VERSION ""

NS_ :

BS_:

BU_: FL_Wheel FR_Wheel BL_Wheel BR_Wheel Brake_Pressure Temp_Board Motion_Board Logger_Board BMS E_Throttle PDM IMD VCU

BO_ 3221225472 VECTOR__INDEPENDENT_SIG_MSG: 0 Vector__XXX
 SG_ Left_ADC : 0|16@1+ (1,0) [0|0] "" Vector__XXX
 SG_ Right_ADC : 16|16@1+ (1,0) [0|0] "" Vector__XXX
 SG_ Brake_ADC : 32|16@1+ (1,0) [0|0] "" Vector__XXX

BO_ 1024 FL_Wheel: 4 FL_Wheel
 SG_ FL_Wheel_Speed : 0|16@1+ (0.1,0) [0|0] "mph" Vector__XXX
 SG_ FL_Brake_Temperature : 16|16@1+ (0.1,-40) [0|0] "C" Vector__XXX

BO_ 1025 FR_Wheel: 4 FR_Wheel
 SG_ FR_Wheel_Speed : 0|16@1+ (0.1,0) [0|0] "mph" Vector__XXX
 SG_ FR_Brake_Temperature : 16|16@1+ (0.1,-40) [0|0] "C" Vector__XXX

BO_ 1026 BL_Wheel: 4 BL_Wheel
 SG_ BL_Wheel_Speed : 0|16@1+ (0.1,0) [0|0] "mph" Vector__XXX
 SG_ BL_Brake_Temperature : 16|16@1+ (0.1,-40) [0|0] "C" Vector__XXX

BO_ 1027 BR_Wheel: 4 BR_Wheel
 SG_ BR_Wheel_Speed : 0|16@1+ (0.1,0) [0|0] "mph" Vector__XXX
 SG_ BR_Brake_Temperature : 16|16@1+ (0.1,-40) [0|0] "C" Vector__XXX

BO_ 1056 Ptrain_Temps: 6 Temp_Board
 SG_ Motor_Temperature : 0|16@1+ (0.1,-40) [0|0] "C" Vector__XXX
 SG_ Coolant_Temperature : 16|16@1+ (0.1,-40) [0|0] "C" Vector__XXX
 SG_ Ambient_Temperature : 32|16@1+ (0.1,-40) [0|0] "C" Vector__XXX

BO_ 1072 GPS: 8 Motion_Board
 SG_ Latitude : 0|32@1- (1,0) [0|0] "1e-7 degrees" Vector__XXX
 SG_ Longitude : 32|32@1- (1,0) [0|0] "1e-7 degrees" Vector__XXX

BO_ 1073 Accelerometer: 6 Motion_Board
 SG_ Accel_X : 0|16@1- (0.0005,0) [0|0] "G" Vector__XXX
 SG_ Accel_Y : 16|16@1- (0.0005,0) [0|0] "G" Vector__XXX
 SG_ Accel_Z : 32|16@1- (0.0005,0) [0|0] "G" Vector__XXX

BO_ 1074 Gyroscope: 6 Motion_Board
 SG_ Gyro_X : 0|16@1- (0.0005,0) [0|0] "rad/s" Vector__XXX
 SG_ Gyro_Y : 16|16@1- (0.0005,0) [0|0] "rad/s" Vector__XXX
 SG_ Gyro_Z : 32|16@1- (0.0005,0) [0|0] "rad/s" Vector__XXX

BO_ 1088 RTC: 4 Logger_Board
 SG_ RTC : 0|32@1+ (1,0) [0|0] "s" Vector__XXX

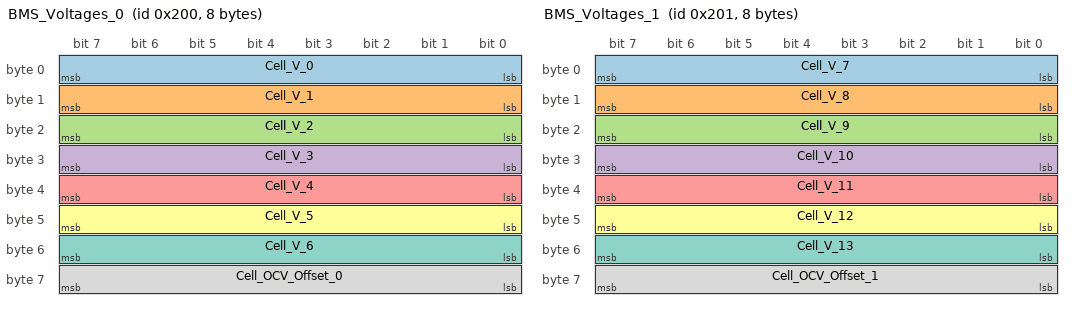
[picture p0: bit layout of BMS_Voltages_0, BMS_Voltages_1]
BO_ 512 BMS_Voltages_0: 8 BMS
 SG_ Cell_V_0 : 0|8@1+ (0.012,2) [0|0] "V" Vector__XXX
 SG_ Cell_V_1 : 8|8@1+ (0.012,2) [0|0] "V" Vector__XXX
 SG_ Cell_V_2 : 16|8@1+ (0.012,2) [0|0] "V" Vector__XXX
 SG_ Cell_V_3 : 24|8@1+ (0.012,2) [0|0] "V" Vector__XXX
 SG_ Cell_V_4 : 32|8@1+ (0.012,2) [0|0] "V" Vector__XXX
 SG_ Cell_V_5 : 40|8@1+ (0.012,2) [0|0] "V" Vector__XXX
 SG_ Cell_V_6 : 48|8@1+ (0.012,2) [0|0] "V" Vector__XXX
 SG_ Cell_OCV_Offset_0 : 56|8@1+ (0.004,0) [0|0] "V" Vector__XXX

BO_ 513 BMS_Voltages_1: 8 BMS
 SG_ Cell_V_7 : 0|8@1+ (0.012,2) [0|0] "V" Vector__XXX
 SG_ Cell_V_8 : 8|8@1+ (0.012,2) [0|0] "V" Vector__XXX
 SG_ Cell_V_9 : 16|8@1+ (0.012,2) [0|0] "V" Vector__XXX
 SG_ Cell_V_10 : 24|8@1+ (0.012,2) [0|0] "V" Vector__XXX
 SG_ Cell_V_11 : 32|8@1+ (0.012,2) [0|0] "V" Vector__XXX
 SG_ Cell_V_12 : 40|8@1+ (0.012,2) [0|0] "V" Vector__XXX
 SG_ Cell_V_13 : 48|8@1+ (0.012,2) [0|0] "V" Vector__XXX
 SG_ Cell_OCV_Offset_1 : 56|8@1+ (0.004,0) [0|0] "V" Vector__XXX

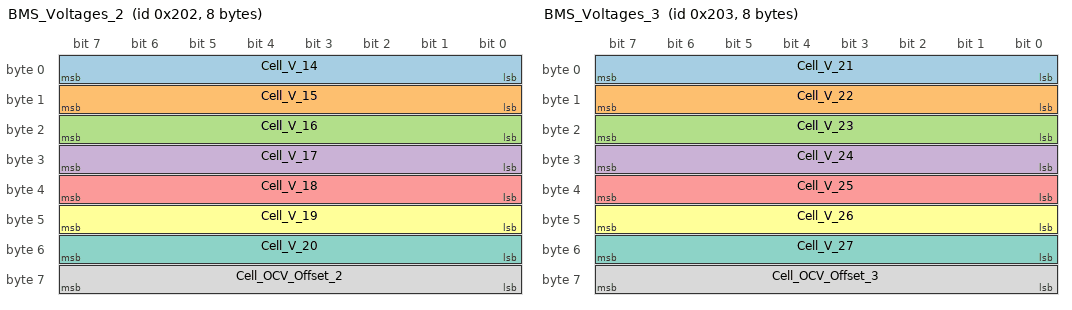
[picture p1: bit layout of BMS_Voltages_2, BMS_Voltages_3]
BO_ 514 BMS_Voltages_2: 8 BMS
 SG_ Cell_V_14 : 0|8@1+ (0.012,2) [0|0] "V" Vector__XXX
 SG_ Cell_V_15 : 8|8@1+ (0.012,2) [0|0] "V" Vector__XXX
 SG_ Cell_V_16 : 16|8@1+ (0.012,2) [0|0] "V" Vector__XXX
 SG_ Cell_V_17 : 24|8@1+ (0.012,2) [0|0] "V" Vector__XXX
 SG_ Cell_V_18 : 32|8@1+ (0.012,2) [0|0] "V" Vector__XXX
 SG_ Cell_V_19 : 40|8@1+ (0.012,2) [0|0] "V" Vector__XXX
 SG_ Cell_V_20 : 48|8@1+ (0.012,2) [0|0] "V" Vector__XXX
 SG_ Cell_OCV_Offset_2 : 56|8@1+ (0.004,0) [0|0] "V" Vector__XXX

BO_ 515 BMS_Voltages_3: 8 BMS
 SG_ Cell_V_21 : 0|8@1+ (0.012,2) [0|0] "V" Vector__XXX
 SG_ Cell_V_22 : 8|8@1+ (0.012,2) [0|0] "V" Vector__XXX
 SG_ Cell_V_23 : 16|8@1+ (0.012,2) [0|0] "V" Vector__XXX
 SG_ Cell_V_24 : 24|8@1+ (0.012,2) [0|0] "V" Vector__XXX
 SG_ Cell_V_25 : 32|8@1+ (0.012,2) [0|0] "V" Vector__XXX
 SG_ Cell_V_26 : 40|8@1+ (0.012,2) [0|0] "V" Vector__XXX
 SG_ Cell_V_27 : 48|8@1+ (0.012,2) [0|0] "V" Vector__XXX
 SG_ Cell_OCV_Offset_3 : 56|8@1+ (0.004,0) [0|0] "V" Vector__XXX

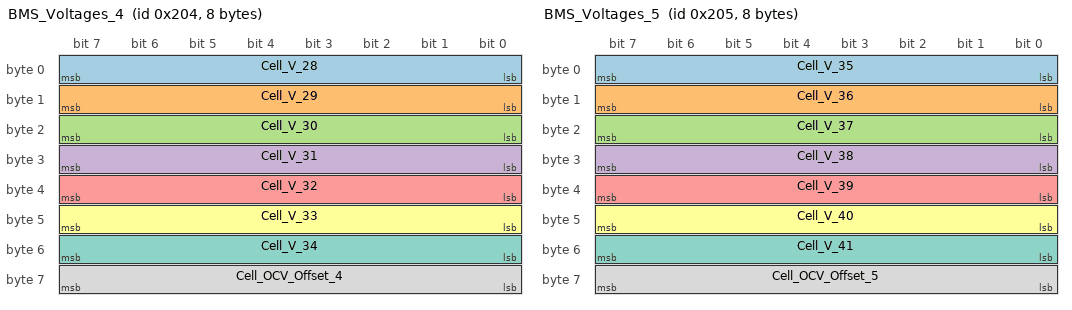
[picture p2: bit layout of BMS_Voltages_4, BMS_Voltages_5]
BO_ 516 BMS_Voltages_4: 8 BMS
 SG_ Cell_V_28 : 0|8@1+ (0.012,2) [0|0] "V" Vector__XXX
 SG_ Cell_V_29 : 8|8@1+ (0.012,2) [0|0] "V" Vector__XXX
 SG_ Cell_V_30 : 16|8@1+ (0.012,2) [0|0] "V" Vector__XXX
 SG_ Cell_V_31 : 24|8@1+ (0.012,2) [0|0] "V" Vector__XXX
 SG_ Cell_V_32 : 32|8@1+ (0.012,2) [0|0] "V" Vector__XXX
 SG_ Cell_V_33 : 40|8@1+ (0.012,2) [0|0] "V" Vector__XXX
 SG_ Cell_V_34 : 48|8@1+ (0.012,2) [0|0] "V" Vector__XXX
 SG_ Cell_OCV_Offset_4 : 56|8@1+ (0.004,0) [0|0] "V" Vector__XXX

BO_ 517 BMS_Voltages_5: 8 BMS
 SG_ Cell_V_35 : 0|8@1+ (0.012,2) [0|0] "V" Vector__XXX
 SG_ Cell_V_36 : 8|8@1+ (0.012,2) [0|0] "V" Vector__XXX
 SG_ Cell_V_37 : 16|8@1+ (0.012,2) [0|0] "V" Vector__XXX
 SG_ Cell_V_38 : 24|8@1+ (0.012,2) [0|0] "V" Vector__XXX
 SG_ Cell_V_39 : 32|8@1+ (0.012,2) [0|0] "V" Vector__XXX
 SG_ Cell_V_40 : 40|8@1+ (0.012,2) [0|0] "V" Vector__XXX
 SG_ Cell_V_41 : 48|8@1+ (0.012,2) [0|0] "V" Vector__XXX
 SG_ Cell_OCV_Offset_5 : 56|8@1+ (0.004,0) [0|0] "V" Vector__XXX

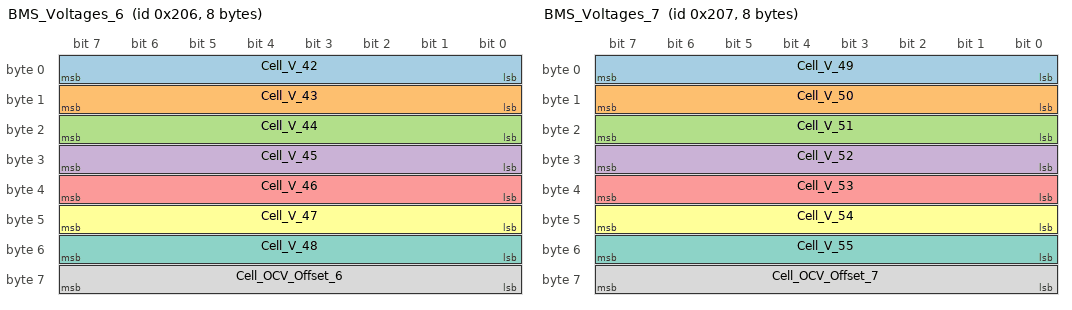
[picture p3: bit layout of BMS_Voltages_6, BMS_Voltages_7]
BO_ 518 BMS_Voltages_6: 8 BMS
 SG_ Cell_V_42 : 0|8@1+ (0.012,2) [0|0] "V" Vector__XXX
 SG_ Cell_V_43 : 8|8@1+ (0.012,2) [0|0] "V" Vector__XXX
 SG_ Cell_V_44 : 16|8@1+ (0.012,2) [0|0] "V" Vector__XXX
 SG_ Cell_V_45 : 24|8@1+ (0.012,2) [0|0] "V" Vector__XXX
 SG_ Cell_V_46 : 32|8@1+ (0.012,2) [0|0] "V" Vector__XXX
 SG_ Cell_V_47 : 40|8@1+ (0.012,2) [0|0] "V" Vector__XXX
 SG_ Cell_V_48 : 48|8@1+ (0.012,2) [0|0] "V" Vector__XXX
 SG_ Cell_OCV_Offset_6 : 56|8@1+ (0.004,0) [0|0] "V" Vector__XXX

BO_ 519 BMS_Voltages_7: 8 BMS
 SG_ Cell_V_49 : 0|8@1+ (0.012,2) [0|0] "V" Vector__XXX
 SG_ Cell_V_50 : 8|8@1+ (0.012,2) [0|0] "V" Vector__XXX
 SG_ Cell_V_51 : 16|8@1+ (0.012,2) [0|0] "V" Vector__XXX
 SG_ Cell_V_52 : 24|8@1+ (0.012,2) [0|0] "V" Vector__XXX
 SG_ Cell_V_53 : 32|8@1+ (0.012,2) [0|0] "V" Vector__XXX
 SG_ Cell_V_54 : 40|8@1+ (0.012,2) [0|0] "V" Vector__XXX
 SG_ Cell_V_55 : 48|8@1+ (0.012,2) [0|0] "V" Vector__XXX
 SG_ Cell_OCV_Offset_7 : 56|8@1+ (0.004,0) [0|0] "V" Vector__XXX

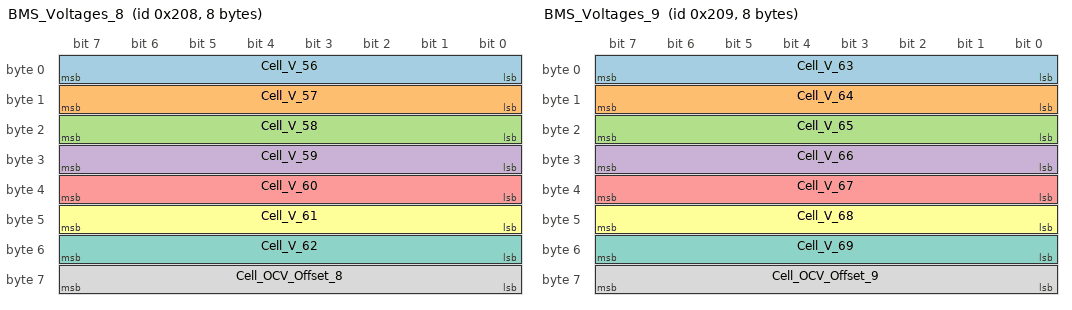
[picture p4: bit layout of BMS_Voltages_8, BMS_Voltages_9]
BO_ 520 BMS_Voltages_8: 8 BMS
 SG_ Cell_V_56 : 0|8@1+ (0.012,2) [0|0] "V" Vector__XXX
 SG_ Cell_V_57 : 8|8@1+ (0.012,2) [0|0] "V" Vector__XXX
 SG_ Cell_V_58 : 16|8@1+ (0.012,2) [0|0] "V" Vector__XXX
 SG_ Cell_V_59 : 24|8@1+ (0.012,2) [0|0] "V" Vector__XXX
 SG_ Cell_V_60 : 32|8@1+ (0.012,2) [0|0] "V" Vector__XXX
 SG_ Cell_V_61 : 40|8@1+ (0.012,2) [0|0] "V" Vector__XXX
 SG_ Cell_V_62 : 48|8@1+ (0.012,2) [0|0] "V" Vector__XXX
 SG_ Cell_OCV_Offset_8 : 56|8@1+ (0.004,0) [0|0] "V" Vector__XXX

BO_ 521 BMS_Voltages_9: 8 BMS
 SG_ Cell_V_63 : 0|8@1+ (0.012,2) [0|0] "V" Vector__XXX
 SG_ Cell_V_64 : 8|8@1+ (0.012,2) [0|0] "V" Vector__XXX
 SG_ Cell_V_65 : 16|8@1+ (0.012,2) [0|0] "V" Vector__XXX
 SG_ Cell_V_66 : 24|8@1+ (0.012,2) [0|0] "V" Vector__XXX
 SG_ Cell_V_67 : 32|8@1+ (0.012,2) [0|0] "V" Vector__XXX
 SG_ Cell_V_68 : 40|8@1+ (0.012,2) [0|0] "V" Vector__XXX
 SG_ Cell_V_69 : 48|8@1+ (0.012,2) [0|0] "V" Vector__XXX
 SG_ Cell_OCV_Offset_9 : 56|8@1+ (0.004,0) [0|0] "V" Vector__XXX

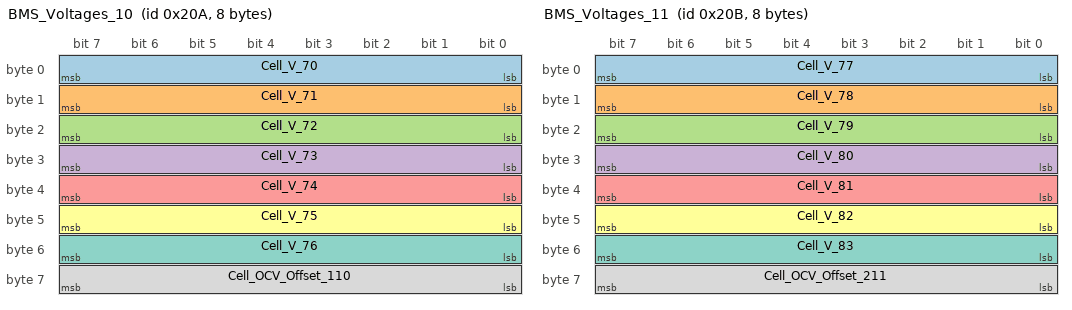
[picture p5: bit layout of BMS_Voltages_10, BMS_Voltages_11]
BO_ 522 BMS_Voltages_10: 8 BMS
 SG_ Cell_V_70 : 0|8@1+ (0.012,2) [0|0] "V" Vector__XXX
 SG_ Cell_V_71 : 8|8@1+ (0.012,2) [0|0] "V" Vector__XXX
 SG_ Cell_V_72 : 16|8@1+ (0.012,2) [0|0] "V" Vector__XXX
 SG_ Cell_V_73 : 24|8@1+ (0.012,2) [0|0] "V" Vector__XXX
 SG_ Cell_V_74 : 32|8@1+ (0.012,2) [0|0] "V" Vector__XXX
 SG_ Cell_V_75 : 40|8@1+ (0.012,2) [0|0] "V" Vector__XXX
 SG_ Cell_V_76 : 48|8@1+ (0.012,2) [0|0] "V" Vector__XXX
 SG_ Cell_OCV_Offset_110 : 56|8@1+ (0.004,0) [0|0] "V" Vector__XXX

BO_ 523 BMS_Voltages_11: 8 BMS
 SG_ Cell_V_77 : 0|8@1+ (0.012,2) [0|0] "V" Vector__XXX
 SG_ Cell_V_78 : 8|8@1+ (0.012,2) [0|0] "V" Vector__XXX
 SG_ Cell_V_79 : 16|8@1+ (0.012,2) [0|0] "V" Vector__XXX
 SG_ Cell_V_80 : 24|8@1+ (0.012,2) [0|0] "V" Vector__XXX
 SG_ Cell_V_81 : 32|8@1+ (0.012,2) [0|0] "V" Vector__XXX
 SG_ Cell_V_82 : 40|8@1+ (0.012,2) [0|0] "V" Vector__XXX
 SG_ Cell_V_83 : 48|8@1+ (0.012,2) [0|0] "V" Vector__XXX
 SG_ Cell_OCV_Offset_211 : 56|8@1+ (0.004,0) [0|0] "V" Vector__XXX

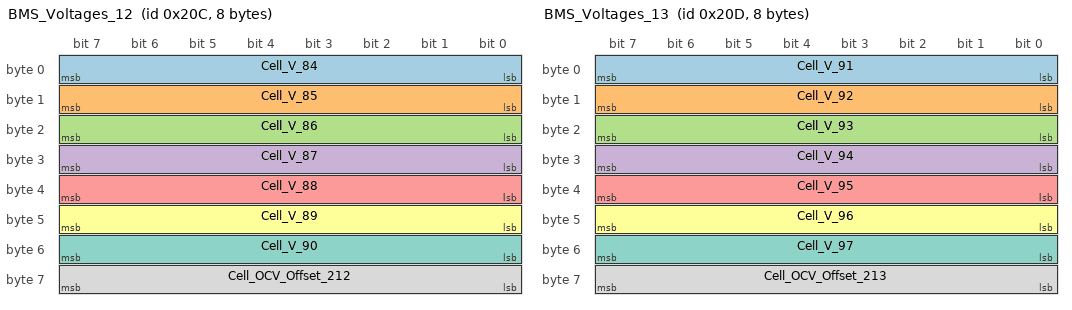
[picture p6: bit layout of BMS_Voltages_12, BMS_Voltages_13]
BO_ 524 BMS_Voltages_12: 8 BMS
 SG_ Cell_V_84 : 0|8@1+ (0.012,2) [0|0] "V" Vector__XXX
 SG_ Cell_V_85 : 8|8@1+ (0.012,2) [0|0] "V" Vector__XXX
 SG_ Cell_V_86 : 16|8@1+ (0.012,2) [0|0] "V" Vector__XXX
 SG_ Cell_V_87 : 24|8@1+ (0.012,2) [0|0] "V" Vector__XXX
 SG_ Cell_V_88 : 32|8@1+ (0.012,2) [0|0] "V" Vector__XXX
 SG_ Cell_V_89 : 40|8@1+ (0.012,2) [0|0] "V" Vector__XXX
 SG_ Cell_V_90 : 48|8@1+ (0.012,2) [0|0] "V" Vector__XXX
 SG_ Cell_OCV_Offset_212 : 56|8@1+ (0.004,0) [0|0] "V" Vector__XXX

BO_ 525 BMS_Voltages_13: 8 BMS
 SG_ Cell_V_91 : 0|8@1+ (0.012,2) [0|0] "V" Vector__XXX
 SG_ Cell_V_92 : 8|8@1+ (0.012,2) [0|0] "V" Vector__XXX
 SG_ Cell_V_93 : 16|8@1+ (0.012,2) [0|0] "V" Vector__XXX
 SG_ Cell_V_94 : 24|8@1+ (0.012,2) [0|0] "V" Vector__XXX
 SG_ Cell_V_95 : 32|8@1+ (0.012,2) [0|0] "V" Vector__XXX
 SG_ Cell_V_96 : 40|8@1+ (0.012,2) [0|0] "V" Vector__XXX
 SG_ Cell_V_97 : 48|8@1+ (0.012,2) [0|0] "V" Vector__XXX
 SG_ Cell_OCV_Offset_213 : 56|8@1+ (0.004,0) [0|0] "V" Vector__XXX

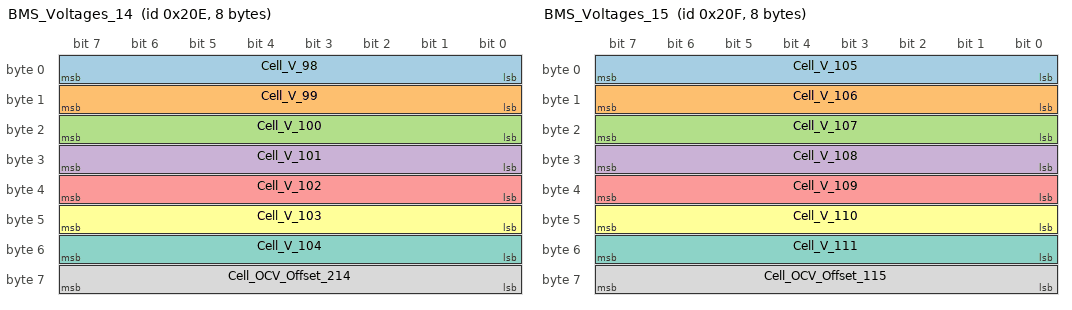
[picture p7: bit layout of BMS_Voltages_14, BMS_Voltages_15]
BO_ 526 BMS_Voltages_14: 8 BMS
 SG_ Cell_V_98 : 0|8@1+ (0.012,2) [0|0] "V" Vector__XXX
 SG_ Cell_V_99 : 8|8@1+ (0.012,2) [0|0] "V" Vector__XXX
 SG_ Cell_V_100 : 16|8@1+ (0.012,2) [0|0] "V" Vector__XXX
 SG_ Cell_V_101 : 24|8@1+ (0.012,2) [0|0] "V" Vector__XXX
 SG_ Cell_V_102 : 32|8@1+ (0.012,2) [0|0] "V" Vector__XXX
 SG_ Cell_V_103 : 40|8@1+ (0.012,2) [0|0] "V" Vector__XXX
 SG_ Cell_V_104 : 48|8@1+ (0.012,2) [0|0] "V" Vector__XXX
 SG_ Cell_OCV_Offset_214 : 56|8@1+ (0.004,0) [0|0] "V" Vector__XXX

BO_ 527 BMS_Voltages_15: 8 BMS
 SG_ Cell_V_105 : 0|8@1+ (0.012,2) [0|0] "V" Vector__XXX
 SG_ Cell_V_106 : 8|8@1+ (0.012,2) [0|0] "V" Vector__XXX
 SG_ Cell_V_107 : 16|8@1+ (0.012,2) [0|0] "V" Vector__XXX
 SG_ Cell_V_108 : 24|8@1+ (0.012,2) [0|0] "V" Vector__XXX
 SG_ Cell_V_109 : 32|8@1+ (0.012,2) [0|0] "V" Vector__XXX
 SG_ Cell_V_110 : 40|8@1+ (0.012,2) [0|0] "V" Vector__XXX
 SG_ Cell_V_111 : 48|8@1+ (0.012,2) [0|0] "V" Vector__XXX
 SG_ Cell_OCV_Offset_115 : 56|8@1+ (0.004,0) [0|0] "V" Vector__XXX

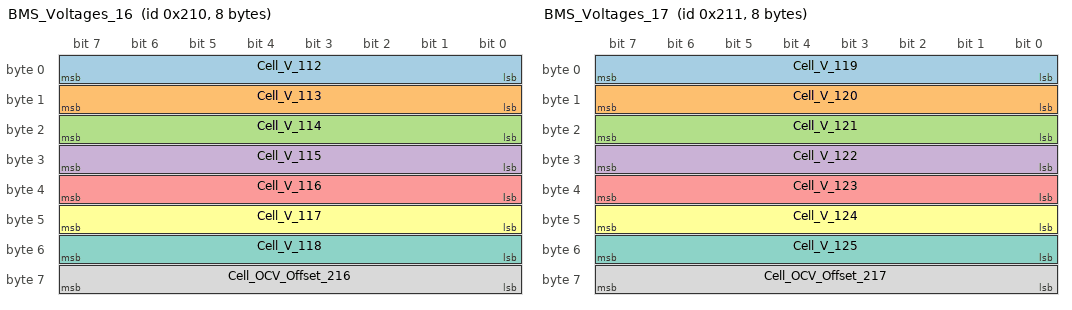
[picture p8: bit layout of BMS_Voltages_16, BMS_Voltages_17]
BO_ 528 BMS_Voltages_16: 8 BMS
 SG_ Cell_V_112 : 0|8@1+ (0.012,2) [0|0] "V" Vector__XXX
 SG_ Cell_V_113 : 8|8@1+ (0.012,2) [0|0] "V" Vector__XXX
 SG_ Cell_V_114 : 16|8@1+ (0.012,2) [0|0] "V" Vector__XXX
 SG_ Cell_V_115 : 24|8@1+ (0.012,2) [0|0] "V" Vector__XXX
 SG_ Cell_V_116 : 32|8@1+ (0.012,2) [0|0] "V" Vector__XXX
 SG_ Cell_V_117 : 40|8@1+ (0.012,2) [0|0] "V" Vector__XXX
 SG_ Cell_V_118 : 48|8@1+ (0.012,2) [0|0] "V" Vector__XXX
 SG_ Cell_OCV_Offset_216 : 56|8@1+ (0.004,0) [0|0] "V" Vector__XXX

BO_ 529 BMS_Voltages_17: 8 BMS
 SG_ Cell_V_119 : 0|8@1+ (0.012,2) [0|0] "V" Vector__XXX
 SG_ Cell_V_120 : 8|8@1+ (0.012,2) [0|0] "V" Vector__XXX
 SG_ Cell_V_121 : 16|8@1+ (0.012,2) [0|0] "V" Vector__XXX
 SG_ Cell_V_122 : 24|8@1+ (0.012,2) [0|0] "V" Vector__XXX
 SG_ Cell_V_123 : 32|8@1+ (0.012,2) [0|0] "V" Vector__XXX
 SG_ Cell_V_124 : 40|8@1+ (0.012,2) [0|0] "V" Vector__XXX
 SG_ Cell_V_125 : 48|8@1+ (0.012,2) [0|0] "V" Vector__XXX
 SG_ Cell_OCV_Offset_217 : 56|8@1+ (0.004,0) [0|0] "V" Vector__XXX

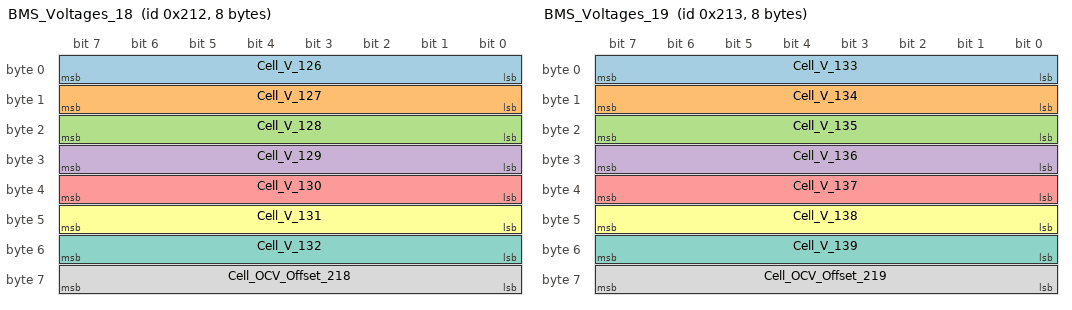
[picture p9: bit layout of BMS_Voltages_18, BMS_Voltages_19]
BO_ 530 BMS_Voltages_18: 8 BMS
 SG_ Cell_V_126 : 0|8@1+ (0.012,2) [0|0] "V" Vector__XXX
 SG_ Cell_V_127 : 8|8@1+ (0.012,2) [0|0] "V" Vector__XXX
 SG_ Cell_V_128 : 16|8@1+ (0.012,2) [0|0] "V" Vector__XXX
 SG_ Cell_V_129 : 24|8@1+ (0.012,2) [0|0] "V" Vector__XXX
 SG_ Cell_V_130 : 32|8@1+ (0.012,2) [0|0] "V" Vector__XXX
 SG_ Cell_V_131 : 40|8@1+ (0.012,2) [0|0] "V" Vector__XXX
 SG_ Cell_V_132 : 48|8@1+ (0.012,2) [0|0] "V" Vector__XXX
 SG_ Cell_OCV_Offset_218 : 56|8@1+ (0.004,0) [0|0] "V" Vector__XXX

BO_ 531 BMS_Voltages_19: 8 BMS
 SG_ Cell_V_133 : 0|8@1+ (0.012,2) [0|0] "V" Vector__XXX
 SG_ Cell_V_134 : 8|8@1+ (0.012,2) [0|0] "V" Vector__XXX
 SG_ Cell_V_135 : 16|8@1+ (0.012,2) [0|0] "V" Vector__XXX
 SG_ Cell_V_136 : 24|8@1+ (0.012,2) [0|0] "V" Vector__XXX
 SG_ Cell_V_137 : 32|8@1+ (0.012,2) [0|0] "V" Vector__XXX
 SG_ Cell_V_138 : 40|8@1+ (0.012,2) [0|0] "V" Vector__XXX
 SG_ Cell_V_139 : 48|8@1+ (0.012,2) [0|0] "V" Vector__XXX
 SG_ Cell_OCV_Offset_219 : 56|8@1+ (0.004,0) [0|0] "V" Vector__XXX

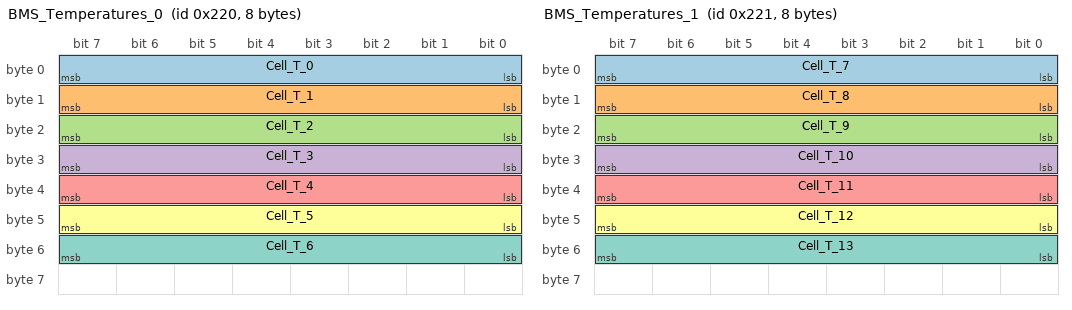
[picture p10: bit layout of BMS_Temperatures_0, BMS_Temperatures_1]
BO_ 544 BMS_Temperatures_0: 8 BMS
 SG_ Cell_T_0 : 0|8@1+ (1,-40) [0|0] "C" Vector__XXX
 SG_ Cell_T_1 : 8|8@1+ (1,-40) [0|0] "C" Vector__XXX
 SG_ Cell_T_2 : 16|8@1+ (1,-40) [0|0] "C" Vector__XXX
 SG_ Cell_T_3 : 24|8@1+ (1,-40) [0|0] "C" Vector__XXX
 SG_ Cell_T_4 : 32|8@1+ (1,-40) [0|0] "C" Vector__XXX
 SG_ Cell_T_5 : 40|8@1+ (1,-40) [0|0] "C" Vector__XXX
 SG_ Cell_T_6 : 48|8@1+ (1,-40) [0|0] "C" Vector__XXX

BO_ 545 BMS_Temperatures_1: 8 BMS
 SG_ Cell_T_7 : 0|8@1+ (1,-40) [0|0] "C" Vector__XXX
 SG_ Cell_T_8 : 8|8@1+ (1,-40) [0|0] "C" Vector__XXX
 SG_ Cell_T_9 : 16|8@1+ (1,-40) [0|0] "C" Vector__XXX
 SG_ Cell_T_10 : 24|8@1+ (1,-40) [0|0] "C" Vector__XXX
 SG_ Cell_T_11 : 32|8@1+ (1,-40) [0|0] "C" Vector__XXX
 SG_ Cell_T_12 : 40|8@1+ (1,-40) [0|0] "C" Vector__XXX
 SG_ Cell_T_13 : 48|8@1+ (1,-40) [0|0] "C" Vector__XXX

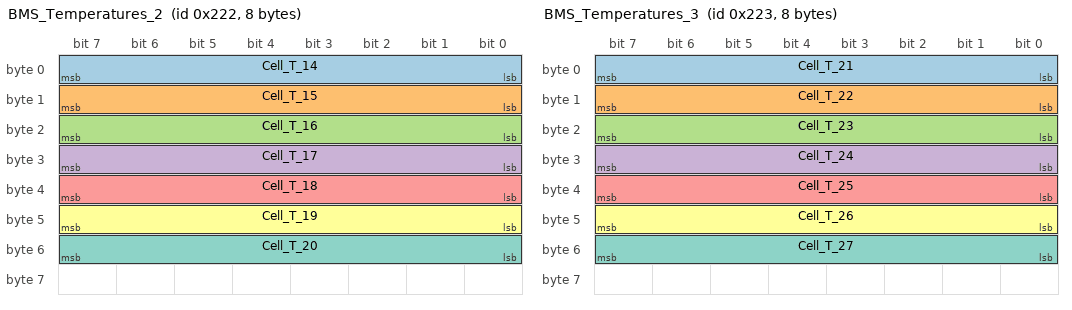
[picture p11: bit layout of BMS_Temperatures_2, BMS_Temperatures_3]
BO_ 546 BMS_Temperatures_2: 8 BMS
 SG_ Cell_T_14 : 0|8@1+ (1,-40) [0|0] "C" Vector__XXX
 SG_ Cell_T_15 : 8|8@1+ (1,-40) [0|0] "C" Vector__XXX
 SG_ Cell_T_16 : 16|8@1+ (1,-40) [0|0] "C" Vector__XXX
 SG_ Cell_T_17 : 24|8@1+ (1,-40) [0|0] "C" Vector__XXX
 SG_ Cell_T_18 : 32|8@1+ (1,-40) [0|0] "C" Vector__XXX
 SG_ Cell_T_19 : 40|8@1+ (1,-40) [0|0] "C" Vector__XXX
 SG_ Cell_T_20 : 48|8@1+ (1,-40) [0|0] "C" Vector__XXX

BO_ 547 BMS_Temperatures_3: 8 BMS
 SG_ Cell_T_21 : 0|8@1+ (1,-40) [0|0] "C" Vector__XXX
 SG_ Cell_T_22 : 8|8@1+ (1,-40) [0|0] "C" Vector__XXX
 SG_ Cell_T_23 : 16|8@1+ (1,-40) [0|0] "C" Vector__XXX
 SG_ Cell_T_24 : 24|8@1+ (1,-40) [0|0] "C" Vector__XXX
 SG_ Cell_T_25 : 32|8@1+ (1,-40) [0|0] "C" Vector__XXX
 SG_ Cell_T_26 : 40|8@1+ (1,-40) [0|0] "C" Vector__XXX
 SG_ Cell_T_27 : 48|8@1+ (1,-40) [0|0] "C" Vector__XXX

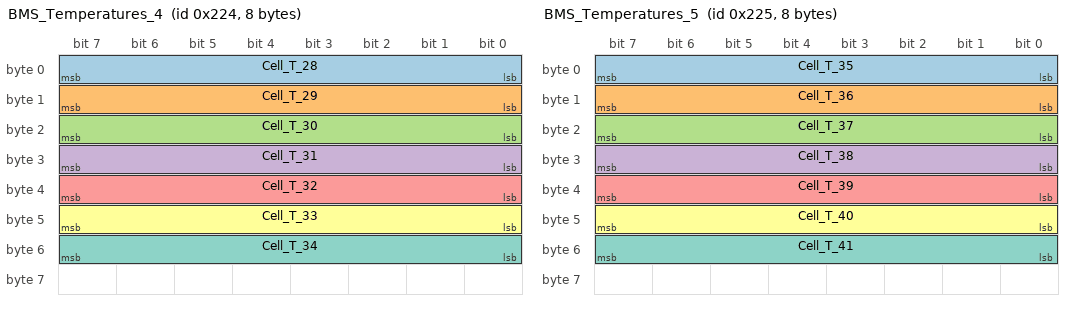
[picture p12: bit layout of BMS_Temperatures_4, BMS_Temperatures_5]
BO_ 548 BMS_Temperatures_4: 8 BMS
 SG_ Cell_T_28 : 0|8@1+ (1,-40) [0|0] "C" Vector__XXX
 SG_ Cell_T_29 : 8|8@1+ (1,-40) [0|0] "C" Vector__XXX
 SG_ Cell_T_30 : 16|8@1+ (1,-40) [0|0] "C" Vector__XXX
 SG_ Cell_T_31 : 24|8@1+ (1,-40) [0|0] "C" Vector__XXX
 SG_ Cell_T_32 : 32|8@1+ (1,-40) [0|0] "C" Vector__XXX
 SG_ Cell_T_33 : 40|8@1+ (1,-40) [0|0] "C" Vector__XXX
 SG_ Cell_T_34 : 48|8@1+ (1,-40) [0|0] "C" Vector__XXX

BO_ 549 BMS_Temperatures_5: 8 BMS
 SG_ Cell_T_35 : 0|8@1+ (1,-40) [0|0] "C" Vector__XXX
 SG_ Cell_T_36 : 8|8@1+ (1,-40) [0|0] "C" Vector__XXX
 SG_ Cell_T_37 : 16|8@1+ (1,-40) [0|0] "C" Vector__XXX
 SG_ Cell_T_38 : 24|8@1+ (1,-40) [0|0] "C" Vector__XXX
 SG_ Cell_T_39 : 32|8@1+ (1,-40) [0|0] "C" Vector__XXX
 SG_ Cell_T_40 : 40|8@1+ (1,-40) [0|0] "C" Vector__XXX
 SG_ Cell_T_41 : 48|8@1+ (1,-40) [0|0] "C" Vector__XXX

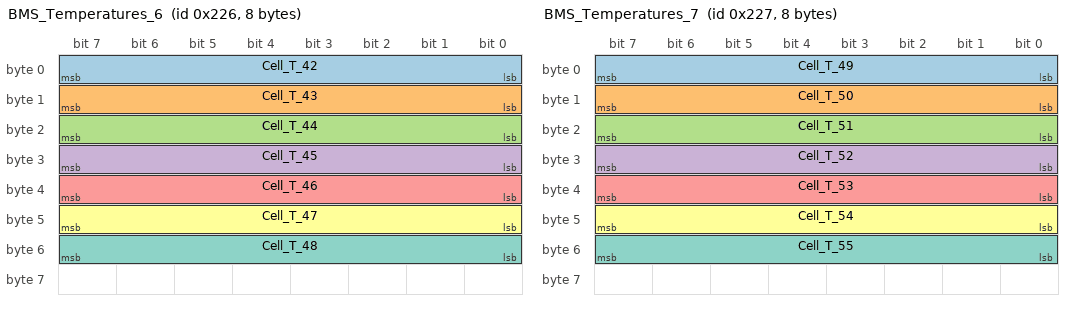
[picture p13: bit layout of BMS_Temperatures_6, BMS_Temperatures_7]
BO_ 550 BMS_Temperatures_6: 8 BMS
 SG_ Cell_T_42 : 0|8@1+ (1,-40) [0|0] "C" Vector__XXX
 SG_ Cell_T_43 : 8|8@1+ (1,-40) [0|0] "C" Vector__XXX
 SG_ Cell_T_44 : 16|8@1+ (1,-40) [0|0] "C" Vector__XXX
 SG_ Cell_T_45 : 24|8@1+ (1,-40) [0|0] "C" Vector__XXX
 SG_ Cell_T_46 : 32|8@1+ (1,-40) [0|0] "C" Vector__XXX
 SG_ Cell_T_47 : 40|8@1+ (1,-40) [0|0] "C" Vector__XXX
 SG_ Cell_T_48 : 48|8@1+ (1,-40) [0|0] "C" Vector__XXX

BO_ 551 BMS_Temperatures_7: 8 BMS
 SG_ Cell_T_49 : 0|8@1+ (1,-40) [0|0] "C" Vector__XXX
 SG_ Cell_T_50 : 8|8@1+ (1,-40) [0|0] "C" Vector__XXX
 SG_ Cell_T_51 : 16|8@1+ (1,-40) [0|0] "C" Vector__XXX
 SG_ Cell_T_52 : 24|8@1+ (1,-40) [0|0] "C" Vector__XXX
 SG_ Cell_T_53 : 32|8@1+ (1,-40) [0|0] "C" Vector__XXX
 SG_ Cell_T_54 : 40|8@1+ (1,-40) [0|0] "C" Vector__XXX
 SG_ Cell_T_55 : 48|8@1+ (1,-40) [0|0] "C" Vector__XXX

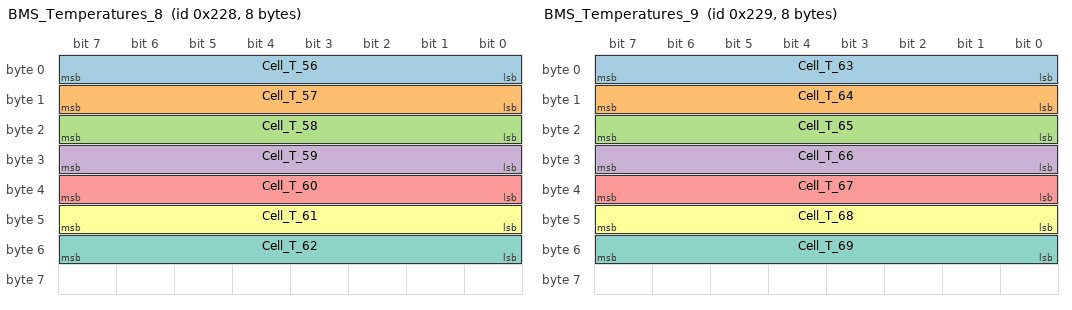
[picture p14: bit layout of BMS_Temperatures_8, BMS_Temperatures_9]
BO_ 552 BMS_Temperatures_8: 8 BMS
 SG_ Cell_T_56 : 0|8@1+ (1,-40) [0|0] "C" Vector__XXX
 SG_ Cell_T_57 : 8|8@1+ (1,-40) [0|0] "C" Vector__XXX
 SG_ Cell_T_58 : 16|8@1+ (1,-40) [0|0] "C" Vector__XXX
 SG_ Cell_T_59 : 24|8@1+ (1,-40) [0|0] "C" Vector__XXX
 SG_ Cell_T_60 : 32|8@1+ (1,-40) [0|0] "C" Vector__XXX
 SG_ Cell_T_61 : 40|8@1+ (1,-40) [0|0] "C" Vector__XXX
 SG_ Cell_T_62 : 48|8@1+ (1,-40) [0|0] "C" Vector__XXX

BO_ 553 BMS_Temperatures_9: 8 BMS
 SG_ Cell_T_63 : 0|8@1+ (1,-40) [0|0] "C" Vector__XXX
 SG_ Cell_T_64 : 8|8@1+ (1,-40) [0|0] "C" Vector__XXX
 SG_ Cell_T_65 : 16|8@1+ (1,-40) [0|0] "C" Vector__XXX
 SG_ Cell_T_66 : 24|8@1+ (1,-40) [0|0] "C" Vector__XXX
 SG_ Cell_T_67 : 32|8@1+ (1,-40) [0|0] "C" Vector__XXX
 SG_ Cell_T_68 : 40|8@1+ (1,-40) [0|0] "C" Vector__XXX
 SG_ Cell_T_69 : 48|8@1+ (1,-40) [0|0] "C" Vector__XXX

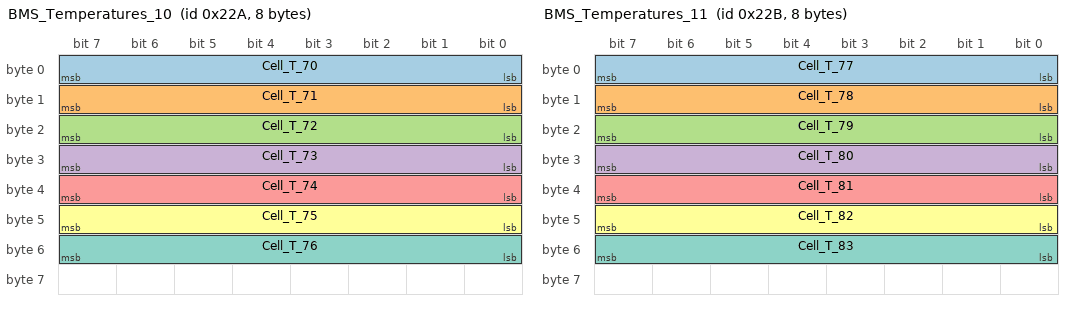
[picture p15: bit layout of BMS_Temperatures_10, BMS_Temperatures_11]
BO_ 554 BMS_Temperatures_10: 8 BMS
 SG_ Cell_T_70 : 0|8@1+ (1,-40) [0|0] "C" Vector__XXX
 SG_ Cell_T_71 : 8|8@1+ (1,-40) [0|0] "C" Vector__XXX
 SG_ Cell_T_72 : 16|8@1+ (1,-40) [0|0] "C" Vector__XXX
 SG_ Cell_T_73 : 24|8@1+ (1,-40) [0|0] "C" Vector__XXX
 SG_ Cell_T_74 : 32|8@1+ (1,-40) [0|0] "C" Vector__XXX
 SG_ Cell_T_75 : 40|8@1+ (1,-40) [0|0] "C" Vector__XXX
 SG_ Cell_T_76 : 48|8@1+ (1,-40) [0|0] "C" Vector__XXX

BO_ 555 BMS_Temperatures_11: 8 BMS
 SG_ Cell_T_77 : 0|8@1+ (1,-40) [0|0] "C" Vector__XXX
 SG_ Cell_T_78 : 8|8@1+ (1,-40) [0|0] "C" Vector__XXX
 SG_ Cell_T_79 : 16|8@1+ (1,-40) [0|0] "C" Vector__XXX
 SG_ Cell_T_80 : 24|8@1+ (1,-40) [0|0] "C" Vector__XXX
 SG_ Cell_T_81 : 32|8@1+ (1,-40) [0|0] "C" Vector__XXX
 SG_ Cell_T_82 : 40|8@1+ (1,-40) [0|0] "C" Vector__XXX
 SG_ Cell_T_83 : 48|8@1+ (1,-40) [0|0] "C" Vector__XXX

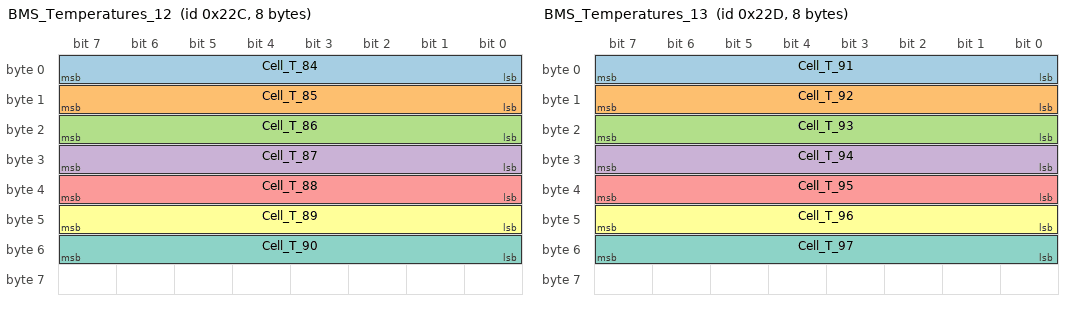
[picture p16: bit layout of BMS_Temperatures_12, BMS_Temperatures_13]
BO_ 556 BMS_Temperatures_12: 8 BMS
 SG_ Cell_T_84 : 0|8@1+ (1,-40) [0|0] "C" Vector__XXX
 SG_ Cell_T_85 : 8|8@1+ (1,-40) [0|0] "C" Vector__XXX
 SG_ Cell_T_86 : 16|8@1+ (1,-40) [0|0] "C" Vector__XXX
 SG_ Cell_T_87 : 24|8@1+ (1,-40) [0|0] "C" Vector__XXX
 SG_ Cell_T_88 : 32|8@1+ (1,-40) [0|0] "C" Vector__XXX
 SG_ Cell_T_89 : 40|8@1+ (1,-40) [0|0] "C" Vector__XXX
 SG_ Cell_T_90 : 48|8@1+ (1,-40) [0|0] "C" Vector__XXX

BO_ 557 BMS_Temperatures_13: 8 BMS
 SG_ Cell_T_91 : 0|8@1+ (1,-40) [0|0] "C" Vector__XXX
 SG_ Cell_T_92 : 8|8@1+ (1,-40) [0|0] "C" Vector__XXX
 SG_ Cell_T_93 : 16|8@1+ (1,-40) [0|0] "C" Vector__XXX
 SG_ Cell_T_94 : 24|8@1+ (1,-40) [0|0] "C" Vector__XXX
 SG_ Cell_T_95 : 32|8@1+ (1,-40) [0|0] "C" Vector__XXX
 SG_ Cell_T_96 : 40|8@1+ (1,-40) [0|0] "C" Vector__XXX
 SG_ Cell_T_97 : 48|8@1+ (1,-40) [0|0] "C" Vector__XXX

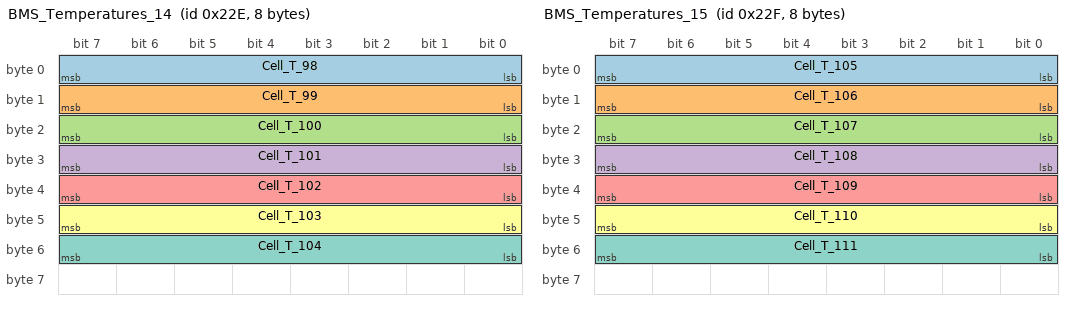
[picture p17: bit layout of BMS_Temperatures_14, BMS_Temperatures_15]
BO_ 558 BMS_Temperatures_14: 8 BMS
 SG_ Cell_T_98 : 0|8@1+ (1,-40) [0|0] "C" Vector__XXX
 SG_ Cell_T_99 : 8|8@1+ (1,-40) [0|0] "C" Vector__XXX
 SG_ Cell_T_100 : 16|8@1+ (1,-40) [0|0] "C" Vector__XXX
 SG_ Cell_T_101 : 24|8@1+ (1,-40) [0|0] "C" Vector__XXX
 SG_ Cell_T_102 : 32|8@1+ (1,-40) [0|0] "C" Vector__XXX
 SG_ Cell_T_103 : 40|8@1+ (1,-40) [0|0] "C" Vector__XXX
 SG_ Cell_T_104 : 48|8@1+ (1,-40) [0|0] "C" Vector__XXX

BO_ 559 BMS_Temperatures_15: 8 BMS
 SG_ Cell_T_105 : 0|8@1+ (1,-40) [0|0] "C" Vector__XXX
 SG_ Cell_T_106 : 8|8@1+ (1,-40) [0|0] "C" Vector__XXX
 SG_ Cell_T_107 : 16|8@1+ (1,-40) [0|0] "C" Vector__XXX
 SG_ Cell_T_108 : 24|8@1+ (1,-40) [0|0] "C" Vector__XXX
 SG_ Cell_T_109 : 32|8@1+ (1,-40) [0|0] "C" Vector__XXX
 SG_ Cell_T_110 : 40|8@1+ (1,-40) [0|0] "C" Vector__XXX
 SG_ Cell_T_111 : 48|8@1+ (1,-40) [0|0] "C" Vector__XXX

BO_ 768 Throttle_Values: 4 E_Throttle
 SG_ Accel_Percentage : 0|8@1- (1,0) [0|0] "" Vector__XXX
 SG_ Brake_Percentage : 8|8@1+ (1,0) [0|0] "" Vector__XXX
 SG_ Torque_Limit_Percentage : 16|8@1+ (1,0) [0|0] "" Vector__XXX
 SG_ Requested_Torque_Percentage : 24|8@1+ (1,0) [0|0] "" Vector__XXX

BO_ 1040 Brake_Pressure: 4 Brake_Pressure
 SG_ Front_Brake_Pressure : 0|16@1+ (1,0) [0|0] "psi" Vector__XXX
 SG_ Back_Brake_Pressure : 16|16@1+ (1,0) [0|0] "psi" Vector__XXX

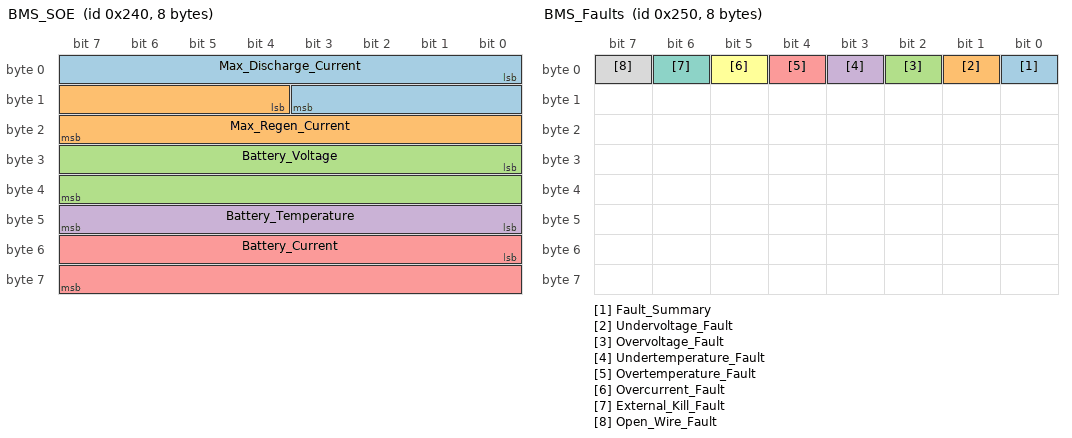
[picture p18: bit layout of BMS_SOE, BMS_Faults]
BO_ 576 BMS_SOE: 8 BMS
 SG_ Max_Discharge_Current : 0|12@1+ (0.1,0) [0|300] "A" Vector__XXX
 SG_ Max_Regen_Current : 12|12@1+ (0.1,0) [0|300] "A" Vector__XXX
 SG_ Battery_Voltage : 24|16@1+ (0.01,0) [0|600] "V" Vector__XXX
 SG_ Battery_Temperature : 40|8@1+ (1,-40) [0|100] "C" Vector__XXX
 SG_ Battery_Current : 48|16@1- (0.01,0) [-300|300] "A" Vector__XXX

BO_ 592 BMS_Faults: 8 BMS
 SG_ Fault_Summary : 0|1@1+ (1,0) [0|0] "" Vector__XXX
 SG_ Undervoltage_Fault : 1|1@1+ (1,0) [0|0] "" Vector__XXX
 SG_ Overvoltage_Fault : 2|1@1+ (1,0) [0|0] "" Vector__XXX
 SG_ Undertemperature_Fault : 3|1@1+ (1,0) [0|0] "" Vector__XXX
 SG_ Overtemperature_Fault : 4|1@1+ (1,0) [0|0] "" Vector__XXX
 SG_ Overcurrent_Fault : 5|1@1+ (1,0) [0|0] "" Vector__XXX
 SG_ External_Kill_Fault : 6|1@1+ (1,0) [0|0] "" Vector__XXX
 SG_ Open_Wire_Fault : 7|1@1+ (1,0) [0|0] "" Vector__XXX

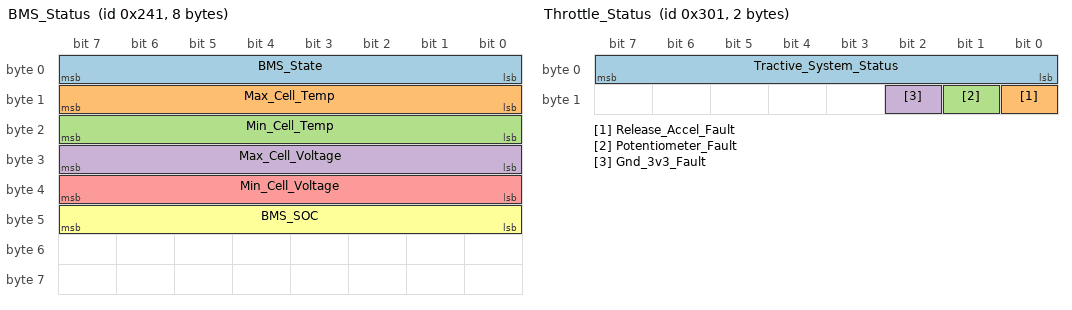
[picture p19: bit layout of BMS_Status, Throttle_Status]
BO_ 577 BMS_Status: 8 BMS
 SG_ BMS_State : 0|8@1+ (1,0) [0|0] "" Vector__XXX
 SG_ Max_Cell_Temp : 8|8@1+ (1,-40) [0|100] "A" Vector__XXX
 SG_ Min_Cell_Temp : 16|8@1+ (1,-40) [0|100] "A" Vector__XXX
 SG_ Max_Cell_Voltage : 24|8@1+ (0.012,2) [0|5] "V" Vector__XXX
 SG_ Min_Cell_Voltage : 32|8@1+ (0.012,2) [0|5] "V" Vector__XXX
 SG_ BMS_SOC : 40|8@1+ (0.5,0) [0|100] "%" Vector__XXX

BO_ 1057 Coolant: 2 Temp_Board
 SG_ Coolant_Flow : 0|16@1+ (0.01,0) [0|0] "L/min" Vector__XXX

BO_ 578 BMS_CMD: 8 Vector__XXX
 SG_ BMS_Command : 0|8@1+ (1,0) [0|0] "" Vector__XXX

BO_ 769 Throttle_Status: 2 E_Throttle
 SG_ Tractive_System_Status : 0|8@1+ (1,0) [0|0] "" Vector__XXX
 SG_ Release_Accel_Fault : 8|1@1+ (1,0) [0|0] "" Vector__XXX
 SG_ Potentiometer_Fault : 9|1@1+ (1,0) [0|0] "" Vector__XXX
 SG_ Gnd_3v3_Fault : 10|1@1+ (1,0) [0|0] "" Vector__XXX

BO_ 1280 PDM_Rails: 6 PDM
 SG_ V5_Rail : 0|8@1+ (0.02,0) [0|0] "A" Vector__XXX
 SG_ V12_Rail : 8|8@1+ (0.02,0) [0|0] "A" Vector__XXX
 SG_ Vbat_Rail : 16|8@1+ (0.02,0) [0|0] "A" Vector__XXX
 SG_ Vbat_Input_Current : 24|16@1- (0.002,0) [0|0] "A" Vector__XXX
 SG_ Vbat_Input_Voltage : 40|8@1+ (0.05,10) [0|0] "V" Vector__XXX

BO_ 1281 PDM_Devices: 5 PDM
 SG_ Air_Cooling_Fan : 0|8@1+ (0.1,0) [0|0] "A" Vector__XXX
 SG_ Liquid_Cooling_Fan : 8|8@1+ (0.1,0) [0|0] "A" Vector__XXX
 SG_ Liquid_Cooling_Pump : 16|8@1+ (0.1,0) [0|0] "A" Vector__XXX
 SG_ High_Side_Driver_1 : 24|8@1+ (0.02,0) [0|0] "A" Vector__XXX
 SG_ High_Side_Driver_2 : 32|8@1+ (0.02,0) [0|0] "A" Vector__XXX

BO_ 1536 IMD: 1 IMD
 SG_ IMD_State : 0|8@1+ (1,0) [0|0] "" Vector__XXX

BO_ 770 Throttle_V: 2 VCU
 SG_ Accelerator_Percentage : 0|8@1+ (1,0) [0|100] "" Vector__XXX
 SG_ Is_Brake_Pressed : 8|1@1+ (1,0) [0|0] "" Vector__XXX
 SG_ Is_Throttle_Active : 9|1@1+ (1,0) [0|0] "" Vector__XXX

CM_ SG_ 1088 RTC "seconds since Jan 1 2000 12AM";
BA_DEF_ BO_  "GenMsgCycleTime" INT 0 10000;
BA_DEF_ BO_  "GenMsgBackgroundColor" STRING ;
BA_DEF_ BO_  "GenMsgForegroundColor" STRING ;
BA_DEF_DEF_  "GenMsgCycleTime" 0;
BA_DEF_DEF_  "GenMsgBackgroundColor" "#1e1e1e";
BA_DEF_DEF_  "GenMsgForegroundColor" "#ffffff";
BA_ "GenMsgCycleTime" BO_ 1024 10;
BA_ "GenMsgCycleTime" BO_ 1025 10;
BA_ "GenMsgCycleTime" BO_ 1026 10;
BA_ "GenMsgCycleTime" BO_ 1027 10;
BA_ "GenMsgCycleTime" BO_ 1056 100;
BA_ "GenMsgCycleTime" BO_ 1072 100;
BA_ "GenMsgCycleTime" BO_ 1073 10;
BA_ "GenMsgCycleTime" BO_ 1074 10;
BA_ "GenMsgCycleTime" BO_ 1088 10;
BA_ "GenMsgCycleTime" BO_ 512 100;
BA_ "GenMsgCycleTime" BO_ 513 100;
BA_ "GenMsgCycleTime" BO_ 514 100;
BA_ "GenMsgCycleTime" BO_ 515 100;
BA_ "GenMsgCycleTime" BO_ 516 100;
BA_ "GenMsgCycleTime" BO_ 517 100;
BA_ "GenMsgCycleTime" BO_ 518 100;
BA_ "GenMsgCycleTime" BO_ 519 100;
BA_ "GenMsgCycleTime" BO_ 520 100;
BA_ "GenMsgCycleTime" BO_ 521 100;
BA_ "GenMsgCycleTime" BO_ 522 100;
BA_ "GenMsgCycleTime" BO_ 523 100;
BA_ "GenMsgCycleTime" BO_ 524 100;
BA_ "GenMsgCycleTime" BO_ 525 100;
BA_ "GenMsgCycleTime" BO_ 526 100;
BA_ "GenMsgCycleTime" BO_ 527 100;
BA_ "GenMsgCycleTime" BO_ 528 100;
BA_ "GenMsgCycleTime" BO_ 529 100;
BA_ "GenMsgCycleTime" BO_ 530 100;
BA_ "GenMsgCycleTime" BO_ 531 100;
BA_ "GenMsgCycleTime" BO_ 544 100;
BA_ "GenMsgCycleTime" BO_ 545 100;
BA_ "GenMsgCycleTime" BO_ 546 100;
BA_ "GenMsgCycleTime" BO_ 547 100;
BA_ "GenMsgCycleTime" BO_ 548 100;
BA_ "GenMsgCycleTime" BO_ 549 100;
BA_ "GenMsgCycleTime" BO_ 550 100;
BA_ "GenMsgCycleTime" BO_ 551 100;
BA_ "GenMsgCycleTime" BO_ 552 100;
BA_ "GenMsgCycleTime" BO_ 553 100;
BA_ "GenMsgCycleTime" BO_ 554 100;
BA_ "GenMsgCycleTime" BO_ 555 100;
BA_ "GenMsgCycleTime" BO_ 556 100;
BA_ "GenMsgCycleTime" BO_ 557 100;
BA_ "GenMsgCycleTime" BO_ 558 100;
BA_ "GenMsgCycleTime" BO_ 559 100;
BA_ "GenMsgCycleTime" BO_ 576 10;
BA_ "GenMsgCycleTime" BO_ 592 100;
BA_ "GenMsgCycleTime" BO_ 577 100;
BA_ "GenMsgCycleTime" BO_ 770 100;
VAL_ 592 Fault_Summary 0 "NotFaulted" 1 "Faulted" ;
VAL_ 592 Undervoltage_Fault 0 "NotFaulted" 1 "Faulted" ;
VAL_ 592 Overvoltage_Fault 0 "NotFaulted" 1 "Faulted" ;
VAL_ 592 Undertemperature_Fault 0 "NotFaulted" 1 "Faulted" ;
VAL_ 592 Overtemperature_Fault 0 "NotFaulted" 1 "Faulted" ;
VAL_ 592 Overcurrent_Fault 0 "NotFaulted" 1 "Faulted" ;
VAL_ 592 External_Kill_Fault 0 "NotFaulted" 1 "Faulted" ;
VAL_ 592 Open_Wire_Fault 0 "NotFaulted" 1 "Faulted" ;
VAL_ 577 BMS_State 0 "Shutdown" 1 "Precharge" 2 "Active" 3 "Charging" 4 "Fault" ;
VAL_ 578 BMS_Command 0 "NoAction" 1 "PrechargeAndCloseContactors" 2 "Shutdown" ;
VAL_ 769 Tractive_System_Status 0 "Off" 1 "Neutral" 2 "Drive" 3 "FaultDrive" ;
VAL_ 769 Release_Accel_Fault 0 "NotFaulted" 1 "Faulted" ;
VAL_ 769 Potentiometer_Fault 0 "NotFaulted" 1 "Faulted" ;
VAL_ 769 Gnd_3v3_Fault 0 "NotFaulted" 1 "Faulted" ;
VAL_ 1536 IMD_State 0 "Active" 1 "Fault" ;
